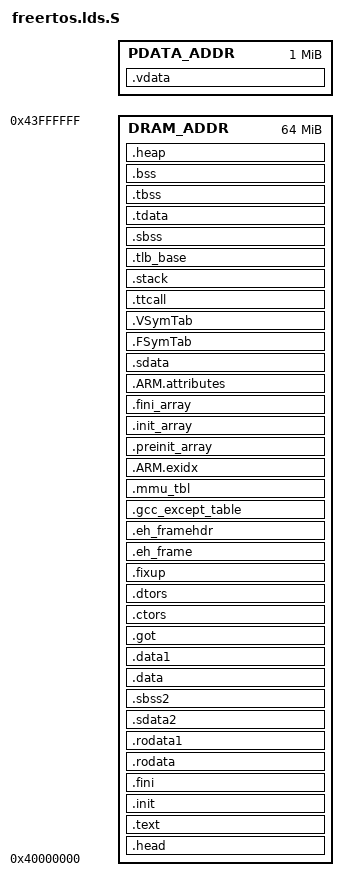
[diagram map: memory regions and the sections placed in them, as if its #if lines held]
/*******************************************************************/
/*                                                                 */
/* This file is automatically generated by linker script generator.*/
/*                                                                 */
/* Version:                                 */
/*                                                                 */
/* Copyright (c) 2010 Xilinx, Inc.  All rights reserved.           */
/*                                                                 */
/* Description : Cortex-A9 Linker Script                          */
/*                                                                 */
/*******************************************************************/

_STACK_SIZE = DEFINED(_STACK_SIZE) ? _STACK_SIZE : 0x4500;

_HEAP_SIZE = DEFINED(_HEAP_SIZE) ? _HEAP_SIZE : CONFIG_TOTAL_HEAP_SIZE;

_TLB_SIZE = DEFINED(_TLB_SIZE) ? _TLB_SIZE : 1024*4;

#ifdef CONFIG_CPU_PRIVATE_DATA
_PDATA_PAGE_ADDR = (CONFIG_CPU_PRIVATE_DATA_ADDR & 0xFFFFF000);
_PDATA_ADDR = (CONFIG_CPU_PRIVATE_DATA_ADDR & 0xFFF00000);
#endif

/* Define Memories in the system */

MEMORY
{
#ifdef CONFIG_CPU_PRIVATE_DATA
   DRAM_ADDR : ORIGIN = 0x40000000, LENGTH = 0x4000000  /* 64M, start from 0x40000000 */
   PDATA_ADDR : ORIGIN = _PDATA_PAGE_ADDR, LENGTH = 0x100000  /* 1M, start from _PDATA_ADDR */
#endif
}

/* Specify the default entry point to the program */

ENTRY(Vectors)

/* Define the sections, and where they are mapped in memory */

SECTIONS
{
.head : {
   __head_start = .;
   KEEP(*(.head))
   __head_end = .;
} > DRAM_ADDR

.text : {
   __text_start = .;
   _mmu_text_start = .;
   KEEP(*(.freertos_vector))
   *(.boot)
   *(.text)
   *(.text.*)
   *(.gnu.linkonce.t.*)
   *(.plt)
   *(.gnu_warning)
   *(.gcc_execpt_table)
   *(.glue_7)
   *(.glue_7t)
   *(.vfp11_veneer)
   *(.ARM.extab)
   *(.gnu.linkonce.armextab.*)
   __text_end = .;
} > DRAM_ADDR

.init : {
   __init_start = .;
   KEEP (*(.init))
   __init_end = .;
} > DRAM_ADDR

.fini : {
   __fini_start = .;
   KEEP (*(.fini))
   __fini_end = .;
} > DRAM_ADDR

.rodata : {
   __rodata_start = .;
   *(.rodata)
   *(.rodata.*)
   *(.gnu.linkonce.r.*)
   __rodata_end = .;
} > DRAM_ADDR

.rodata1 : {
   __rodata1_start = .;
   *(.rodata1)
   *(.rodata1.*)
   __rodata1_end = .;
   _mmu_text_end = .;
} > DRAM_ADDR

.sdata2 : {
   __sdata2_start = .;
   *(.sdata2)
   *(.sdata2.*)
   *(.gnu.linkonce.s2.*)
   __sdata2_end = .;
} > DRAM_ADDR

.sbss2 : {
   __sbss2_start = .;
   *(.sbss2)
   *(.sbss2.*)
   *(.gnu.linkonce.sb2.*)
   __sbss2_end = .;
} > DRAM_ADDR

.data : {
   __data_start = .;
   *(.data)
   *(.data.*)
   *(.gnu.linkonce.d.*)
   *(.jcr)
   *(.got)
   *(.got.plt)
   __data_end = .;
} > DRAM_ADDR

.data1 : {
   __data1_start = .;
   *(.data1)
   *(.data1.*)
   __data1_end = .;
} > DRAM_ADDR

.got : {
   __got_start = .;
   *(.got)
   __got_end = .;
} > DRAM_ADDR

.ctors : {
   __CTOR_LIST__ = .;
   ___CTORS_LIST___ = .;
   KEEP (*crtbegin.o(.ctors))
   KEEP (*(EXCLUDE_FILE(*crtend.o) .ctors))
   KEEP (*(SORT(.ctors.*)))
   KEEP (*(.ctors))
   __CTOR_END__ = .;
   ___CTORS_END___ = .;
} > DRAM_ADDR

.dtors : {
   __DTOR_LIST__ = .;
   ___DTORS_LIST___ = .;
   KEEP (*crtbegin.o(.dtors))
   KEEP (*(EXCLUDE_FILE(*crtend.o) .dtors))
   KEEP (*(SORT(.dtors.*)))
   KEEP (*(.dtors))
   __DTOR_END__ = .;
   ___DTORS_END___ = .;
} > DRAM_ADDR

.fixup : {
   __fixup_start = .;
   *(.fixup)
   __fixup_end = .;
} > DRAM_ADDR

.eh_frame : {
   __en_frame_start = .;
   *(.eh_frame)
   __en_frame_end = .;
} > DRAM_ADDR

.eh_framehdr : {
   __eh_framehdr_start = .;
   *(.eh_framehdr)
   __eh_framehdr_end = .;
} > DRAM_ADDR

.gcc_except_table : {
   __gcc_except_table_start = .;
   *(.gcc_except_table)
   __gcc_except_table_end = .;
} > DRAM_ADDR

.mmu_tbl (ALIGN(16384)) : {
   __mmu_tbl_start = .;
   *(.mmu_tbl)
   __mmu_tbl_end = .;
} > DRAM_ADDR

.ARM.exidx : {
   __exidx_start = .;
   *(.ARM.exidx*)
   *(.gnu.linkonce.armexidix.*.*)
   __exidx_end = .;
} > DRAM_ADDR

.preinit_array : {
   __preinit_array_start = .;
   KEEP (*(SORT(.preinit_array.*)))
   KEEP (*(.preinit_array))
   __preinit_array_end = .;
} > DRAM_ADDR

.init_array : {
   __init_array_start = .;
   KEEP (*(SORT(.init_array.*)))
   KEEP (*(.init_array))
   __init_array_end = .;
} > DRAM_ADDR

.fini_array : {
   __fini_array_start = .;
   KEEP (*(SORT(.fini_array.*)))
   KEEP (*(.fini_array))
   __fini_array_end = .;
} > DRAM_ADDR

.ARM.attributes : {
   __attributes_start = .;
   __ARM.attributes_start = .;
   *(.ARM.attributes)
   __ARM.attributes_end = .;
   __attributes_end = .;
} > DRAM_ADDR

.sdata : {
   __sdata_start = .;
   *(.sdata)
   *(.sdata.*)
   *(.gnu.linkonce.s.*)
   __sdata_end = .;
} > DRAM_ADDR

.FSymTab : {
   _syscall_table_begin = .;
   KEEP(*(FSymTab))
   _syscall_table_end = .;
} > DRAM_ADDR

.VSymTab : {
   __vsymtab_start = .;
   KEEP(*(VSymTab))
   __vsymtab_end = .;
} > DRAM_ADDR

.ttcall : {
   _tt_begin = .;
   KEEP(*(ttcall))
   _tt_end = .;
   _tt_auto_begin = .;
   KEEP(*(auto_ttcall))
   _tt_auto_end = .;
} > DRAM_ADDR

.stack (NOLOAD) : {
   . = ALIGN(16);
   _stack_end = .;
   _cpu1_stack_end = .;
   . += _STACK_SIZE;
   _cpu1_stack_start = .;
   _cpu0_stack_end = .;
   . += _STACK_SIZE;
   . = ALIGN(16);
   _stack_start = .;
} > DRAM_ADDR

.tlb_base (NOLOAD) : {
   . = ALIGN(16);
   __tlb_base_entry = .;
   . += _TLB_SIZE;
   . = ALIGN(16);
   __tlb_base_end = .;
} > DRAM_ADDR

.sbss (NOLOAD) : {
   __sbss_start = .;
   *(.sbss)
   *(.sbss.*)
   *(.gnu.linkonce.sb.*)
   __sbss_end = .;
} > DRAM_ADDR

.tdata : {
   __tdata_start = .;
   *(.tdata)
   *(.tdata.*)
   *(.gnu.linkonce.td.*)
   __tdata_end = .;
} > DRAM_ADDR

.tbss : {
   __tbss_start = .;
   *(.tbss)
   *(.tbss.*)
   *(.gnu.linkonce.tb.*)
   __tbss_end = .;
} > DRAM_ADDR

.bss (NOLOAD) : {
   __bss_start = .;
   *(.bss)
   *(.bss.*)
   *(.gnu.linkonce.b.*)
   *(COMMON)
   __bss_end = .;
} > DRAM_ADDR

PROVIDE (end = .);

_SDA_BASE_ = __sdata_start + ((__sbss_end - __sdata_start) / 2 );

_SDA2_BASE_ = __sdata2_start + ((__sbss2_end - __sdata2_start) / 2 );

/* Generate Stack and Heap definitions */

.heap (NOLOAD) : {
   . = ALIGN(16);
   _heap = .;
   ucHeap = .;
   HeapBase = .;
   _heap_start = .;
   . += _HEAP_SIZE;
   _heap_end = .;
   HeapLimit = .;
} > DRAM_ADDR

#ifdef CONFIG_CPU_PRIVATE_DATA
.vdata (NOLOAD): {
  . = ALIGN(16);
   *(.vdata)
   *(.vdata.*)
} > PDATA_ADDR
_end = .;
#endif
}

